# M3H6 register map
File version: 0.1
Registers are 32-bit, read-write, reset 0x0 unless marked. A register's access mark holds for its fields unless they carry their own. Offsets are from the block's base; [hi:lo] are bit positions; {n}, {i} and the like mark numbered series.

## PK
Base 0x400C0900
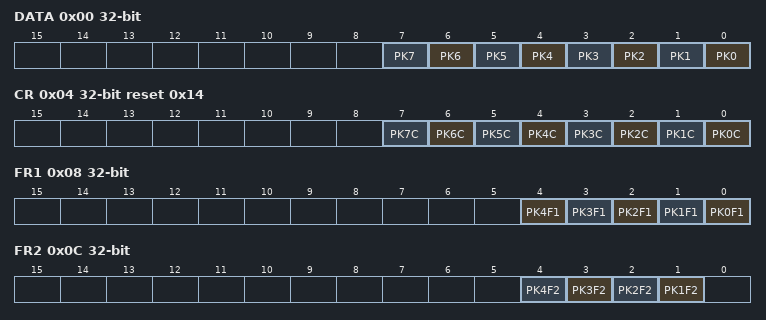
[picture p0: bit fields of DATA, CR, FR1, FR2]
0x00 DATA — PK Data Register
  [n] PK{n} (n=0..7)
0x04 CR reset 0x14 — PK Control Register
  [n] PK{n}C (n=0..7)
0x08 FR1 — PK Function Register 1
  [n] PK{n}F1 (n=0..4)
0x0C FR2 — PK Function Register 2
  [n] PK{n}F2 (n=1..4)
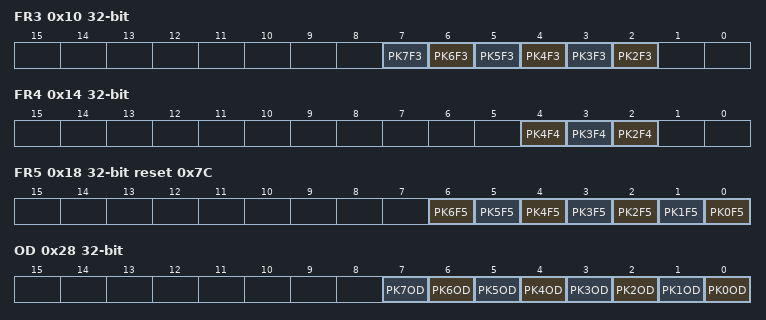
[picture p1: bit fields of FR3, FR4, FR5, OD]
0x10 FR3 — PK Function Register 3
  [n] PK{n}F3 (n=2..7)
0x14 FR4 — PK Function Register 4
  [4] PK4F4, [3] PK3F4, [2] PK2F4
0x18 FR5 reset 0x7C — PK Function Register 5
  [n] PK{n}F5 (n=0..6)
0x28 OD — PK Open Drain Control Register
  [n] PK{n}OD (n=0..7)
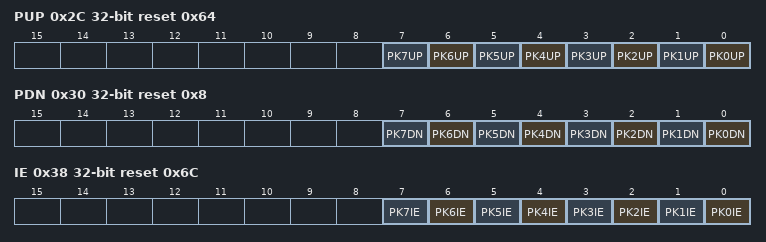
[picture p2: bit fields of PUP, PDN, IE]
0x2C PUP reset 0x64 — PK Pull-up Control Register
  [n] PK{n}UP (n=0..7)
0x30 PDN reset 0x8 — PK Pull-Down Control Register
  [n] PK{n}DN (n=0..7)
0x38 IE reset 0x6C — PK Input Enable Control Register
  [n] PK{n}IE (n=0..7)

## PL
Base 0x400C0A00
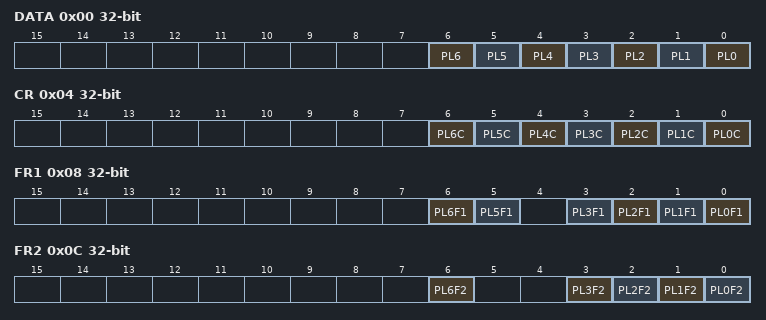
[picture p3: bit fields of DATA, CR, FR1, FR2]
0x00 DATA — PL Data Register
  [n] PL{n} (n=0..6)
0x04 CR — PL Control Register
  [n] PL{n}C (n=0..6)
0x08 FR1 — PL Function Register 1
  [6] PL6F1, [5] PL5F1, [n] PL{n}F1 (n=0..3)
0x0C FR2 — PL Function Register 2
  [6] PL6F2, [n] PL{n}F2 (n=0..3)
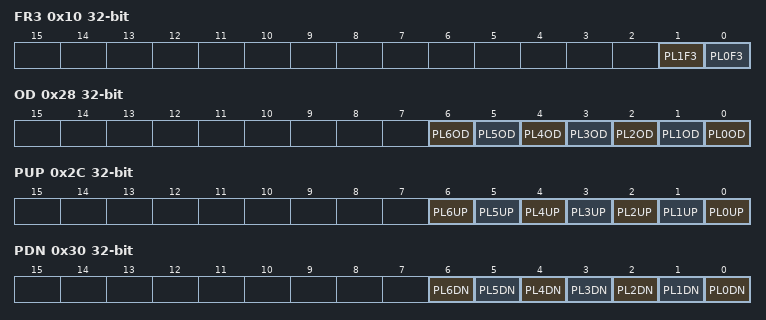
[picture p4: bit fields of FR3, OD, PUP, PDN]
0x10 FR3 — PL Function Register 3
  [1] PL1F3, [0] PL0F3
0x28 OD — PL Open Drain Control Register
  [n] PL{n}OD (n=0..6)
0x2C PUP — PL Pull-up Control Register
  [n] PL{n}UP (n=0..6)
0x30 PDN — PL Pull-Down Control Register
  [n] PL{n}DN (n=0..6)
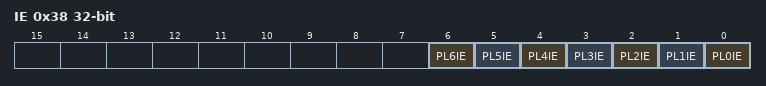
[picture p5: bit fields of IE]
0x38 IE — PL Input Enable Control Register
  [n] PL{n}IE (n=0..6)

## PM
Base 0x400C0B00
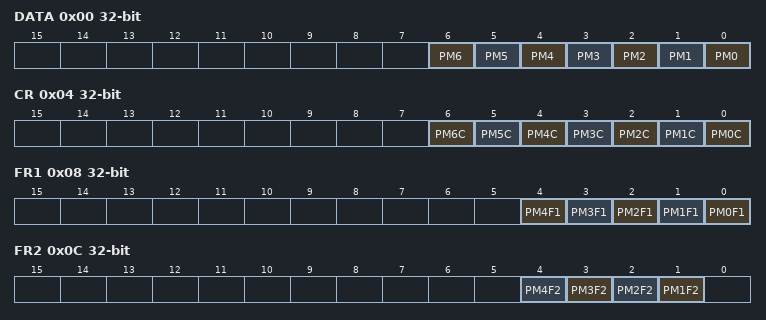
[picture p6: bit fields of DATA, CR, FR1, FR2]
0x00 DATA — PM Data Register
  [n] PM{n} (n=0..6)
0x04 CR — PM Control Register
  [n] PM{n}C (n=0..6)
0x08 FR1 — PM Function Register 1
  [n] PM{n}F1 (n=0..4)
0x0C FR2 — PM Function Register 2
  [n] PM{n}F2 (n=1..4)
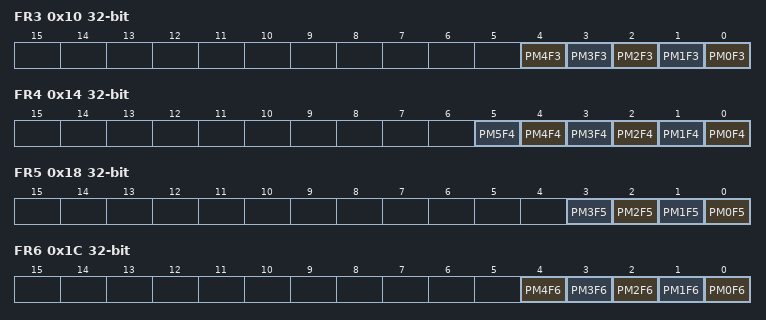
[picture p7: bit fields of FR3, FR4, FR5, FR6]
0x10 FR3 — PM Function Register 3
  [n] PM{n}F3 (n=0..4)
0x14 FR4 — PM Function Register 4
  [n] PM{n}F4 (n=0..5)
0x18 FR5 — PM Function Register 5
  [n] PM{n}F5 (n=0..3)
0x1C FR6 — PM Function Register 6
  [n] PM{n}F6 (n=0..4)
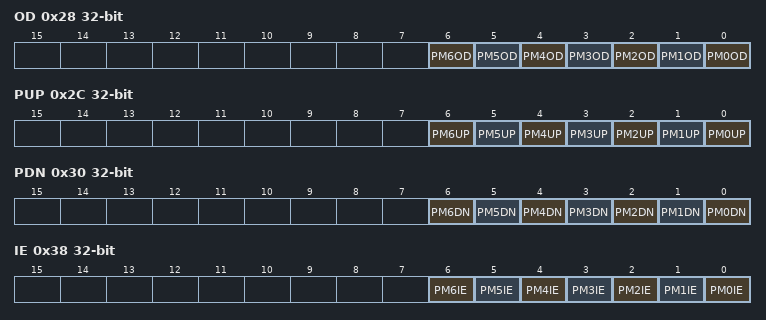
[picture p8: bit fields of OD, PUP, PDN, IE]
0x28 OD — PM Open Drain Control Register
  [n] PM{n}OD (n=0..6)
0x2C PUP — PM Pull-up Control Register
  [n] PM{n}UP (n=0..6)
0x30 PDN — PM Pull-Down Control Register
  [n] PM{n}DN (n=0..6)
0x38 IE — PM Input Enable Control Register
  [n] PM{n}IE (n=0..6)

## PN
Base 0x400C0C00
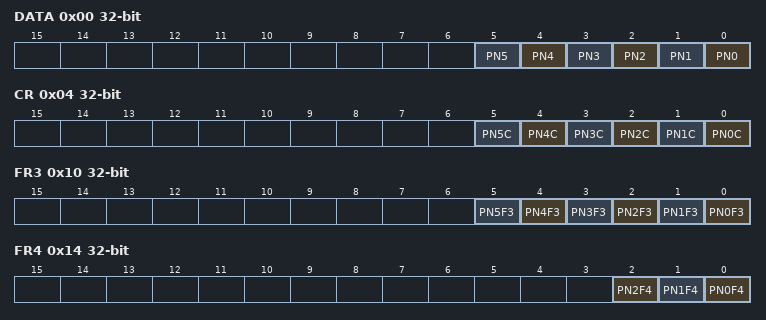
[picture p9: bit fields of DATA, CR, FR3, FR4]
0x00 DATA — PN Data Register
  [n] PN{n} (n=0..5)
0x04 CR — PN Control Register
  [n] PN{n}C (n=0..5)
0x10 FR3 — PN Function Register 3
  [n] PN{n}F3 (n=0..5)
0x14 FR4 — PN Function Register 4
  [2] PN2F4, [1] PN1F4, [0] PN0F4
0x18 FR5 — PN Function Register 5
  [3] PN3F5
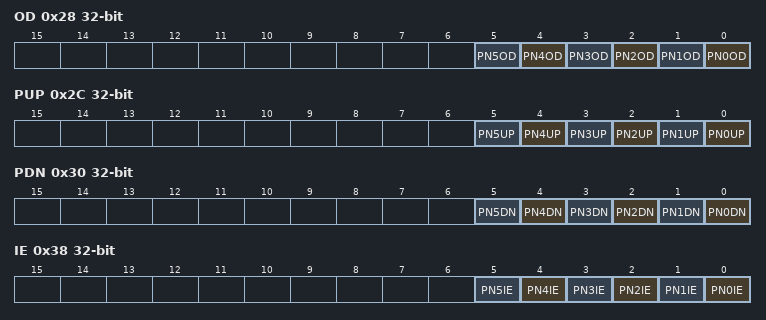
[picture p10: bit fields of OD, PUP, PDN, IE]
0x28 OD — PN Open Drain Control Register
  [n] PN{n}OD (n=0..5)
0x2C PUP — PN Pull-up Control Register
  [n] PN{n}UP (n=0..5)
0x30 PDN — PN Pull-Down Control Register
  [n] PN{n}DN (n=0..5)
0x38 IE — PN Input Enable Control Register
  [n] PN{n}IE (n=0..5)

## PP
Base 0x400C0D00
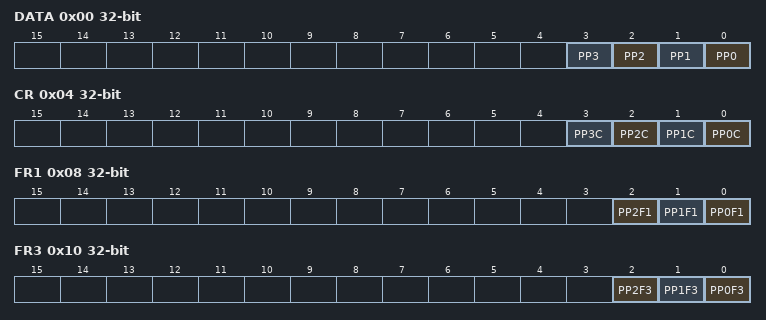
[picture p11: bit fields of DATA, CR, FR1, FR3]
0x00 DATA — PP Data Register
  [n] PP{n} (n=0..3)
0x04 CR — PP Control Register
  [n] PP{n}C (n=0..3)
0x08 FR1 — PP Function Register 1
  [2] PP2F1, [1] PP1F1, [0] PP0F1
0x10 FR3 — PP Function Register 3
  [2] PP2F3, [1] PP1F3, [0] PP0F3
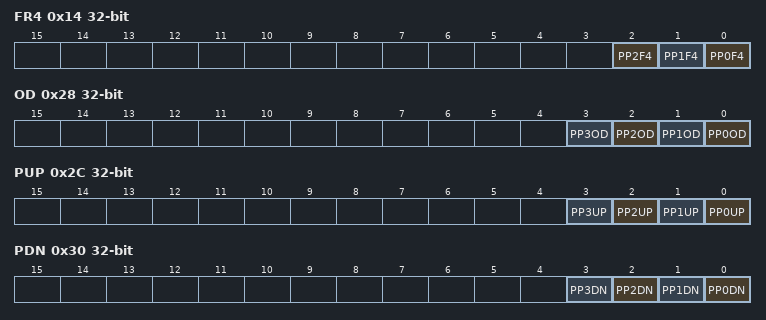
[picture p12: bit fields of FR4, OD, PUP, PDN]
0x14 FR4 — PP Function Register 4
  [2] PP2F4, [1] PP1F4, [0] PP0F4
0x28 OD — PP Open Drain Control Register
  [n] PP{n}OD (n=0..3)
0x2C PUP — PP Pull-up Control Register
  [n] PP{n}UP (n=0..3)
0x30 PDN — PP Pull-Down Control Register
  [n] PP{n}DN (n=0..3)
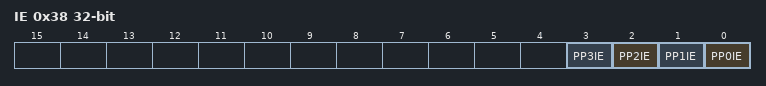
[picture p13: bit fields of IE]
0x38 IE — PP Input Enable Control Register
  [n] PP{n}IE (n=0..3)

## PR
Base 0x400C0E00
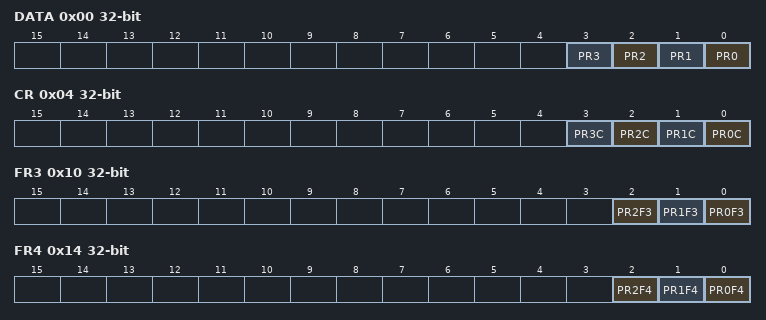
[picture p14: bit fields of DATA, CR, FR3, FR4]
0x00 DATA — PR Data Register
  [n] PR{n} (n=0..3)
0x04 CR — PR Control Register
  [n] PR{n}C (n=0..3)
0x10 FR3 — PR Function Register 3
  [2] PR2F3, [1] PR1F3, [0] PR0F3
0x14 FR4 — PR Function Register 4
  [2] PR2F4, [1] PR1F4, [0] PR0F4
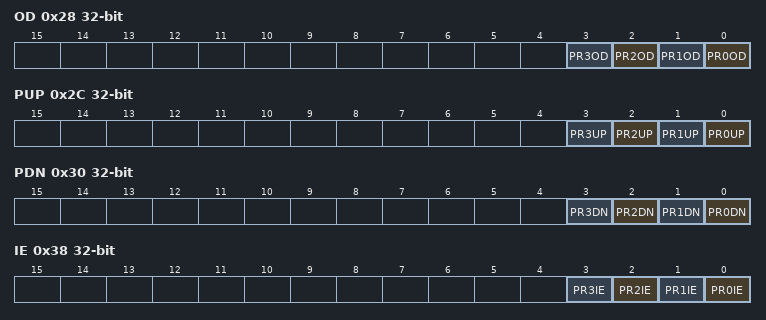
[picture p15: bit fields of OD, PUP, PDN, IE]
0x28 OD — PR Open Drain Control Register
  [n] PR{n}OD (n=0..3)
0x2C PUP — PR Pull-up Control Register
  [n] PR{n}UP (n=0..3)
0x30 PDN — PR Pull-Down Control Register
  [n] PR{n}DN (n=0..3)
0x38 IE — PR Input Enable Control Register
  [n] PR{n}IE (n=0..3)
